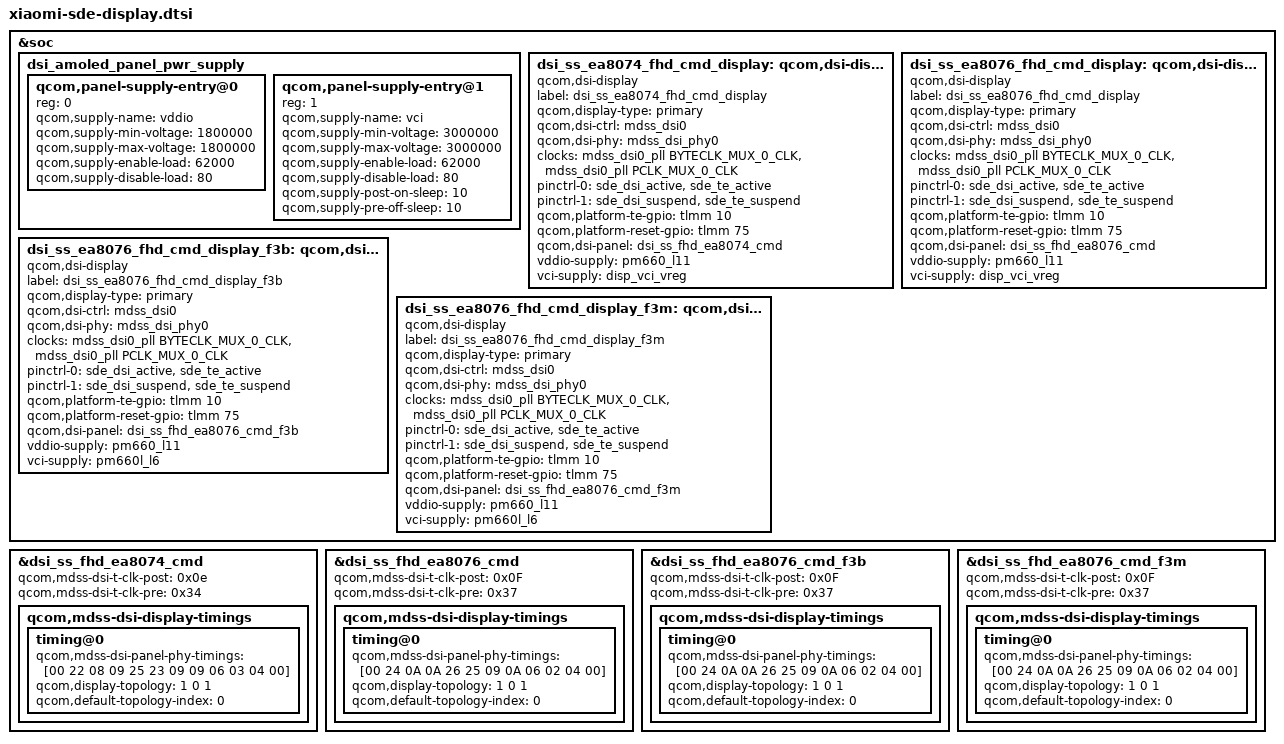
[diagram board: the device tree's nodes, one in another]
/* Copyright (c) 2017, The Linux Foundation. All rights reserved.
 * Copyright (C) 2019 XiaoMi, Inc.
 *
 * This program is free software; you can redistribute it and/or modify
 * it under the terms of the GNU General Public License version 2 and
 * only version 2 as published by the Free Software Foundation.
 *
 * This program is distributed in the hope that it will be useful,
 * but WITHOUT ANY WARRANTY; without even the implied warranty of
 * MERCHANTABILITY or FITNESS FOR A PARTICULAR PURPOSE.  See the
 * GNU General Public License for more details.
 */

#include "dsi-panel-ss-fhd-ea8074-cmd.dtsi"
#include "dsi-panel-samsung-fhd-ea8076-cmd.dtsi"
#include "dsi-panel-samsung-fhd-ea8076-cmd-f3b.dtsi"
#include "dsi-panel-samsung-fhd-ea8076-cmd-f3m.dtsi"

&soc {
	dsi_amoled_panel_pwr_supply: dsi_amoled_panel_pwr_supply {
		#address-cells = <1>;
		#size-cells = <0>;

		qcom,panel-supply-entry@0 {
			reg = <0>;
			qcom,supply-name = "vddio";
			qcom,supply-min-voltage = <1800000>;
			qcom,supply-max-voltage = <1800000>;
			qcom,supply-enable-load = <62000>;
			qcom,supply-disable-load = <80>;
		};

		qcom,panel-supply-entry@1 {
			reg = <1>;
			qcom,supply-name = "vci";
			qcom,supply-min-voltage = <3000000>;
			qcom,supply-max-voltage = <3000000>;
			qcom,supply-enable-load = <62000>;
			qcom,supply-disable-load = <80>;
			qcom,supply-post-on-sleep = <10>;
			qcom,supply-pre-off-sleep = <10>;
		};
	};

	dsi_ss_ea8074_fhd_cmd_display: qcom,dsi-display@17 {
		compatible = "qcom,dsi-display";
		label = "dsi_ss_ea8074_fhd_cmd_display";
		qcom,display-type = "primary";

		qcom,dsi-ctrl = <&mdss_dsi0>;
		qcom,dsi-phy = <&mdss_dsi_phy0>;
		clocks = <&mdss_dsi0_pll BYTECLK_MUX_0_CLK>,
			<&mdss_dsi0_pll PCLK_MUX_0_CLK>;
		clock-names = "mux_byte_clk", "mux_pixel_clk";

		pinctrl-names = "panel_active", "panel_suspend";
		pinctrl-0 = <&sde_dsi_active &sde_te_active>;
		pinctrl-1 = <&sde_dsi_suspend &sde_te_suspend>;
		qcom,platform-te-gpio = <&tlmm 10 0>;
		qcom,platform-reset-gpio = <&tlmm 75 0>;
		/*qcom,panel-errfg-gpio = <&tlmm 122 0>;*/

		qcom,dsi-panel = <&dsi_ss_fhd_ea8074_cmd>;
		vddio-supply = <&pm660_l11>;
		vci-supply = <&disp_vci_vreg>;
	};

	dsi_ss_ea8076_fhd_cmd_display: qcom,dsi-display@18 {
		compatible = "qcom,dsi-display";
		label = "dsi_ss_ea8076_fhd_cmd_display";
		qcom,display-type = "primary";

		qcom,dsi-ctrl = <&mdss_dsi0>;
		qcom,dsi-phy = <&mdss_dsi_phy0>;
		clocks = <&mdss_dsi0_pll BYTECLK_MUX_0_CLK>,
			<&mdss_dsi0_pll PCLK_MUX_0_CLK>;
		clock-names = "mux_byte_clk", "mux_pixel_clk";

		pinctrl-names = "panel_active", "panel_suspend";
		pinctrl-0 = <&sde_dsi_active &sde_te_active>;
		pinctrl-1 = <&sde_dsi_suspend &sde_te_suspend>;
		qcom,platform-te-gpio = <&tlmm 10 0>;
		qcom,platform-reset-gpio = <&tlmm 75 0>;
		/*qcom,panel-errfg-gpio = <&tlmm 78 0>;*/

		qcom,dsi-panel = <&dsi_ss_fhd_ea8076_cmd>;
		vddio-supply = <&pm660_l11>;
		vci-supply = <&disp_vci_vreg>;
	};

	dsi_ss_ea8076_fhd_cmd_display_f3b: qcom,dsi-display@19 {
		compatible = "qcom,dsi-display";
		label = "dsi_ss_ea8076_fhd_cmd_display_f3b";
		qcom,display-type = "primary";

		qcom,dsi-ctrl = <&mdss_dsi0>;
		qcom,dsi-phy = <&mdss_dsi_phy0>;
		clocks = <&mdss_dsi0_pll BYTECLK_MUX_0_CLK>,
			<&mdss_dsi0_pll PCLK_MUX_0_CLK>;
		clock-names = "mux_byte_clk", "mux_pixel_clk";

		pinctrl-names = "panel_active", "panel_suspend";
		pinctrl-0 = <&sde_dsi_active &sde_te_active>;
		pinctrl-1 = <&sde_dsi_suspend &sde_te_suspend>;
		qcom,platform-te-gpio = <&tlmm 10 0>;
		qcom,platform-reset-gpio = <&tlmm 75 0>;
		/*qcom,panel-errfg-gpio = <&tlmm 78 0>;*/

		qcom,dsi-panel = <&dsi_ss_fhd_ea8076_cmd_f3b>;
		vddio-supply = <&pm660_l11>;
		vci-supply = <&pm660l_l6>;
	};

	dsi_ss_ea8076_fhd_cmd_display_f3m: qcom,dsi-display@20 {
		compatible = "qcom,dsi-display";
		label = "dsi_ss_ea8076_fhd_cmd_display_f3m";
		qcom,display-type = "primary";

		qcom,dsi-ctrl = <&mdss_dsi0>;
		qcom,dsi-phy = <&mdss_dsi_phy0>;
		clocks = <&mdss_dsi0_pll BYTECLK_MUX_0_CLK>,
			<&mdss_dsi0_pll PCLK_MUX_0_CLK>;
		clock-names = "mux_byte_clk", "mux_pixel_clk";

		pinctrl-names = "panel_active", "panel_suspend";
		pinctrl-0 = <&sde_dsi_active &sde_te_active>;
		pinctrl-1 = <&sde_dsi_suspend &sde_te_suspend>;
		qcom,platform-te-gpio = <&tlmm 10 0>;
		qcom,platform-reset-gpio = <&tlmm 75 0>;
		/*qcom,panel-errfg-gpio = <&tlmm 78 0>;*/

		qcom,dsi-panel = <&dsi_ss_fhd_ea8076_cmd_f3m>;
		vddio-supply = <&pm660_l11>;
		vci-supply = <&pm660l_l6>;
	};
};

&dsi_ss_fhd_ea8074_cmd {
	qcom,mdss-dsi-t-clk-post = <0x0e>;
	qcom,mdss-dsi-t-clk-pre = <0x34>;
	qcom,mdss-dsi-display-timings {
		timing@0{
			qcom,mdss-dsi-panel-phy-timings = [00 22 08 09 25 23 09
				09 06 03 04 00];
			qcom,display-topology = <1 0 1>;
			qcom,default-topology-index = <0>;
		};
	};
};

&dsi_ss_fhd_ea8076_cmd {
	qcom,mdss-dsi-t-clk-post = <0x0F>;
	qcom,mdss-dsi-t-clk-pre = <0x37>;
	qcom,mdss-dsi-display-timings {
		timing@0{
			qcom,mdss-dsi-panel-phy-timings = [00 24 0A 0A 26 25 09
				0A 06 02 04 00];
			qcom,display-topology = <1 0 1>;
			qcom,default-topology-index = <0>;
		};
	};
};

&dsi_ss_fhd_ea8076_cmd_f3b {
	qcom,mdss-dsi-t-clk-post = <0x0F>;
	qcom,mdss-dsi-t-clk-pre = <0x37>;
	qcom,mdss-dsi-display-timings {
		timing@0{
			qcom,mdss-dsi-panel-phy-timings = [00 24 0A 0A 26 25 09
				0A 06 02 04 00];
			qcom,display-topology = <1 0 1>;
			qcom,default-topology-index = <0>;
		};
	};
};

&dsi_ss_fhd_ea8076_cmd_f3m {
	qcom,mdss-dsi-t-clk-post = <0x0F>;
	qcom,mdss-dsi-t-clk-pre = <0x37>;
	qcom,mdss-dsi-display-timings {
		timing@0{
			qcom,mdss-dsi-panel-phy-timings = [00 24 0A 0A 26 25 09
				0A 06 02 04 00];
			qcom,display-topology = <1 0 1>;
			qcom,default-topology-index = <0>;
		};
	};
};
